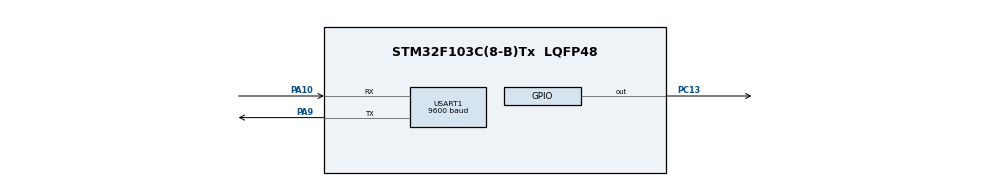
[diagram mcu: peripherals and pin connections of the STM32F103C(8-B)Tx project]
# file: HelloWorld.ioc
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Mcu.Family=STM32F1
Mcu.Name=STM32F103C(8-B)Tx
Mcu.Package=LQFP48
NVIC.PriorityGroup=NVIC_PRIORITYGROUP_4
PA10.Mode=Asynchronous
PA10.Signal=USART1_RX
PA13.Mode=Serial_Wire
PA13.Signal=SYS_JTMS-SWDIO
PA14.Mode=Serial_Wire
PA14.Signal=SYS_JTCK-SWCLK
PA9.Mode=Asynchronous
PA9.Signal=USART1_TX
PC13-TAMPER-RTC.Signal=GPIO_Output
PD0-OSC_IN.Mode=HSE-External-Oscillator
PD0-OSC_IN.Signal=RCC_OSC_IN
PD1-OSC_OUT.Mode=HSE-External-Oscillator
PD1-OSC_OUT.Signal=RCC_OSC_OUT
ProjectManager.HeapSize=0x200
ProjectManager.StackSize=0x400
ProjectManager.TargetToolchain=CMake
RCC.APB1Freq_Value=8000000
RCC.APB2Freq_Value=8000000
USART1.BaudRate=9600
USART1.VirtualMode=VM_ASYNC
board=custom

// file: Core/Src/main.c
/* USER CODE BEGIN Header */
/**
 ******************************************************************************
 * @file           : main.c
 * @brief          : Main program body
 ******************************************************************************
 * @attention
 *
 * Copyright (c) 2025 STMicroelectronics.
 * All rights reserved.
 *
 * This software is licensed under terms that can be found in the LICENSE file
 * in the root directory of this software component.
 * If no LICENSE file comes with this software, it is provided AS-IS.
 *
 ******************************************************************************
 */
/* USER CODE END Header */
#include "main.h"
#include "usart.h"
#include "gpio.h"
#include "uart_lak.h"
#include "my_cpp_lib.h"
#include "wrapper.h"
#include <stdlib.h>

void SystemClock_Config(void);

int main(void)
{

  /* MCU Configuration--------------------------------------------------------*/

  /* Reset of all peripherals, Initializes the Flash interface and the Systick. */
  HAL_Init();

  /* Configure the system clock */
  SystemClock_Config();

  /* Initialize all configured peripherals */
  MX_GPIO_Init();
  MX_USART1_UART_Init();
  /* USER CODE BEGIN 2 */
  void *cppObj = MyCppClass_create();
  MyCppClass_sayHello(cppObj);

  void *unixStamp = UnixStamp_create();
  char timeStr[] = "23/04/25,14:30:00+07";
  uint32_t unixTime = UnixStamp_convertToUnix(unixStamp, timeStr);
  char *dayStr = UnixStamp_convertToDay(unixStamp, unixTime);
  uint32_t hours = 0;
  char *dateStr = UnixStamp_convertToDate(unixStamp, timeStr, &hours);

  void *calcValue = CalculateValue_create();
  uint16_t ledBefore[] = {1000, 2000, 3000, 4000, 5000, 6000};
  uint16_t ledAfter[] = {900, 1800, 2700, 3600, 4500, 5400};
  float coef[] = {6.487};
  float inter = -0.416;
  uint8_t leds[] = {3};
  float value = CalculateValue_findValue(calcValue, ledBefore, ledAfter, 1, 1, coef, &inter, leds, 1);
  bool hasError = CalculateValue_checkErr(calcValue, ledBefore, ledAfter, 1);

  free(dayStr);
  free(dateStr);
  UnixStamp_destroy(unixStamp);
  CalculateValue_destroy(calcValue);
  /* USER CODE END 2 */

  /* Infinite loop */
  while (1)
  {

    /* USER CODE BEGIN 3 */
  }
  MyCppClass_destroy(cppObj);
  /* USER CODE END 3 */
}

void SystemClock_Config(void)
{
  RCC_OscInitTypeDef RCC_OscInitStruct = {0};
  RCC_ClkInitTypeDef RCC_ClkInitStruct = {0};

  /** Initializes the RCC Oscillators according to the specified parameters
   * in the RCC_OscInitTypeDef structure.
   */
  RCC_OscInitStruct.OscillatorType = RCC_OSCILLATORTYPE_HSI;
  RCC_OscInitStruct.HSIState = RCC_HSI_ON;
  RCC_OscInitStruct.HSICalibrationValue = RCC_HSICALIBRATION_DEFAULT;
  RCC_OscInitStruct.PLL.PLLState = RCC_PLL_NONE;
  if (HAL_RCC_OscConfig(&RCC_OscInitStruct) != HAL_OK)
  {
    Error_Handler();
  }

  /** Initializes the CPU, AHB and APB buses clocks
   */
  RCC_ClkInitStruct.ClockType = RCC_CLOCKTYPE_HCLK | RCC_CLOCKTYPE_SYSCLK | RCC_CLOCKTYPE_PCLK1 | RCC_CLOCKTYPE_PCLK2;
  RCC_ClkInitStruct.SYSCLKSource = RCC_SYSCLKSOURCE_HSI;
  RCC_ClkInitStruct.AHBCLKDivider = RCC_SYSCLK_DIV1;
  RCC_ClkInitStruct.APB1CLKDivider = RCC_HCLK_DIV1;
  RCC_ClkInitStruct.APB2CLKDivider = RCC_HCLK_DIV1;

  if (HAL_RCC_ClockConfig(&RCC_ClkInitStruct, FLASH_LATENCY_0) != HAL_OK)
  {
    Error_Handler();
  }
}

void Error_Handler(void)
{
  __disable_irq();
  while (1)
  {
  }
}
